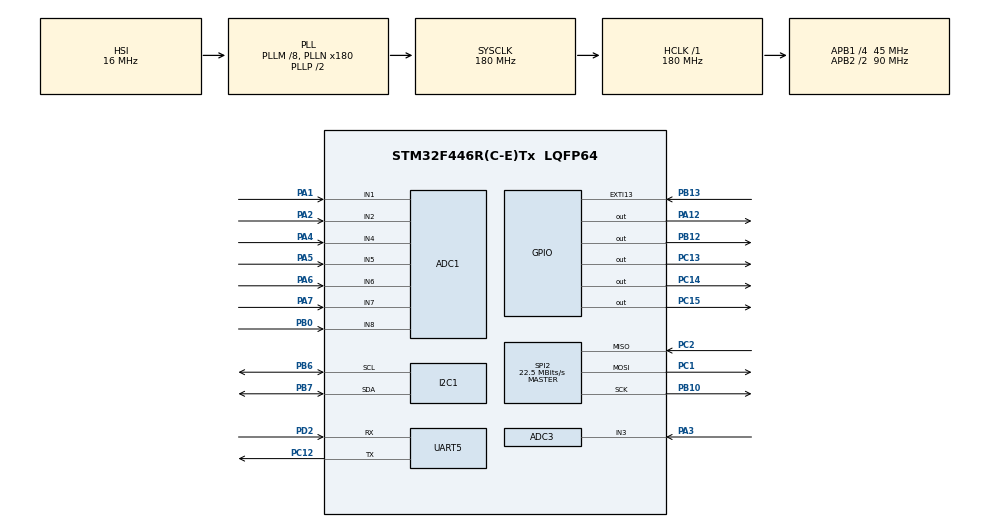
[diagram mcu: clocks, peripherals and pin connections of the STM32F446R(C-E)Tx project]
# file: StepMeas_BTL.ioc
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ADC1.Channel-0\#ChannelRegularConversion=ADC_CHANNEL_7
ADC1.Channel-1\#ChannelRegularConversion=ADC_CHANNEL_8
ADC1.Channel-2\#ChannelRegularConversion=ADC_CHANNEL_1
ADC1.Channel-3\#ChannelRegularConversion=ADC_CHANNEL_2
ADC1.ClockPrescaler=ADC_CLOCK_SYNC_PCLK_DIV6
ADC1.NbrOfConversion=4
ADC1.NbrOfConversionFlag=1
ADC1.Rank-0\#ChannelRegularConversion=1
ADC1.Rank-1\#ChannelRegularConversion=2
ADC1.Rank-2\#ChannelRegularConversion=3
ADC1.Rank-3\#ChannelRegularConversion=4
ADC1.SamplingTime-0\#ChannelRegularConversion=ADC_SAMPLETIME_3CYCLES
ADC1.SamplingTime-1\#ChannelRegularConversion=ADC_SAMPLETIME_3CYCLES
ADC1.SamplingTime-2\#ChannelRegularConversion=ADC_SAMPLETIME_3CYCLES
ADC1.SamplingTime-3\#ChannelRegularConversion=ADC_SAMPLETIME_3CYCLES
ADC1.master=1
ADC3.Channel-0\#ChannelRegularConversion=ADC_CHANNEL_3
ADC3.ClockPrescaler=ADC_CLOCK_SYNC_PCLK_DIV6
ADC3.NbrOfConversionFlag=1
ADC3.Rank-0\#ChannelRegularConversion=1
ADC3.SamplingTime-0\#ChannelRegularConversion=ADC_SAMPLETIME_3CYCLES
Dma.ADC1.0.Direction=DMA_PERIPH_TO_MEMORY
Dma.ADC1.0.FIFOMode=DMA_FIFOMODE_DISABLE
Dma.ADC1.0.Instance=DMA2_Stream0
Dma.ADC1.0.MemDataAlignment=DMA_MDATAALIGN_HALFWORD
Dma.ADC1.0.MemInc=DMA_MINC_ENABLE
Dma.ADC1.0.Mode=DMA_NORMAL
Dma.ADC1.0.PeriphDataAlignment=DMA_PDATAALIGN_HALFWORD
Dma.ADC1.0.PeriphInc=DMA_PINC_DISABLE
Dma.ADC1.0.Priority=DMA_PRIORITY_LOW
Dma.Request0=ADC1
IWDG.Prescaler=IWDG_PRESCALER_32
IWDG.Reload=3500
Mcu.Family=STM32F4
Mcu.Name=STM32F446R(C-E)Tx
Mcu.Package=LQFP64
NVIC.DMA2_Stream0_IRQn=true\:0\:0\:false\:false\:true\:false\:true\:true
NVIC.EXTI15_10_IRQn=true\:0\:0\:false\:false\:true\:true\:true\:true
NVIC.PriorityGroup=NVIC_PRIORITYGROUP_4
NVIC.TIM2_IRQn=true\:0\:0\:false\:false\:true\:true\:true\:true
NVIC.TIM8_TRG_COM_TIM14_IRQn=true\:0\:0\:false\:false\:true\:true\:true\:true
PA1.Signal=ADCx_IN1
PA12.GPIO_PuPd=GPIO_PULLUP
PA12.Signal=GPIO_Output
PA13.Mode=Serial_Wire
PA13.Signal=SYS_JTMS-SWDIO
PA14.Mode=Serial_Wire
PA14.Signal=SYS_JTCK-SWCLK
PA2.Signal=ADCx_IN2
PA3.Signal=ADCx_IN3
PA4.Signal=ADCx_IN4
PA5.Signal=ADCx_IN5
PA6.Signal=ADCx_IN6
PA7.Signal=ADCx_IN7
PB0.Signal=ADCx_IN8
PB10.Mode=Full_Duplex_Master
PB10.Signal=SPI2_SCK
PB12.Signal=GPIO_Output
PB13.Signal=GPXTI13
PB6.Mode=I2C
PB6.Signal=I2C1_SCL
PB7.Mode=I2C
PB7.Signal=I2C1_SDA
PC1.Mode=Full_Duplex_Master
PC1.Signal=SPI2_MOSI
PC12.Mode=Asynchronous
PC12.Signal=UART5_TX
PC13.Signal=GPIO_Output
PC14-OSC32_IN.Signal=GPIO_Output
PC15-OSC32_OUT.Signal=GPIO_Output
PC2.Mode=Full_Duplex_Master
PC2.Signal=SPI2_MISO
PD2.Mode=Asynchronous
PD2.Signal=UART5_RX
PH0-OSC_IN.Mode=HSE-External-Oscillator
PH0-OSC_IN.Signal=RCC_OSC_IN
PH1-OSC_OUT.Mode=HSE-External-Oscillator
PH1-OSC_OUT.Signal=RCC_OSC_OUT
ProjectManager.HeapSize=0x200
ProjectManager.StackSize=0x400
ProjectManager.TargetToolchain=STM32CubeIDE
RCC.48MHZClocksFreq_Value=48000000
RCC.AHBFreq_Value=180000000
RCC.APB1CLKDivider=RCC_HCLK_DIV4
RCC.APB1Freq_Value=45000000
RCC.APB1TimFreq_Value=90000000
RCC.APB2CLKDivider=RCC_HCLK_DIV2
RCC.APB2Freq_Value=90000000
RCC.APB2TimFreq_Value=180000000
RCC.CortexFreq_Value=180000000
RCC.HCLKFreq_Value=180000000
RCC.HSE_VALUE=25000000
RCC.HSI_VALUE=16000000
RCC.PLLM=8
RCC.PLLN=180
RCC.PLLQ=7
RCC.SYSCLKFreq_VALUE=180000000
RCC.SYSCLKSource=RCC_SYSCLKSOURCE_PLLCLK
RCC.USBFreq_Value=51428571.428571425
RCC.VCOOutputFreq_Value=360000000
SH.ADCx_IN1.0=ADC1_IN1,IN1
SH.ADCx_IN2.0=ADC1_IN2,IN2
SH.ADCx_IN3.0=ADC3_IN3,IN3
SH.ADCx_IN3.1=ADC1_IN3,IN3
SH.ADCx_IN4.0=ADC1_IN4,IN4
SH.ADCx_IN5.0=ADC1_IN5,IN5
SH.ADCx_IN6.0=ADC1_IN6,IN6
SH.ADCx_IN7.0=ADC1_IN7,IN7
SH.ADCx_IN8.0=ADC1_IN8,IN8
SPI2.BaudRatePrescaler=SPI_BAUDRATEPRESCALER_2
SPI2.CalculateBaudRate=22.5 MBits/s
SPI2.Direction=SPI_DIRECTION_2LINES
SPI2.Mode=SPI_MODE_MASTER
SPI2.VirtualType=VM_MASTER
TIM14.Period=1000
TIM14.Prescaler=8399
TIM2.Period=55-1
TIM2.Prescaler=45
UART5.VirtualMode=Asynchronous
VP_CRC_VS_CRC.Mode=CRC_Activate
VP_IWDG_VS_IWDG.Mode=IWDG_Activate
VP_TIM14_VS_ClockSourceINT.Mode=Enable_Timer
VP_TIM2_VS_ClockSourceINT.Mode=Internal
board=custom

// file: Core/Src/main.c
/* USER CODE BEGIN Header */
/**
  ******************************************************************************
  * @file           : main.c
  * @brief          : Main program body
  ******************************************************************************
  * @attention
  *
  * <h2><center>&copy; Copyright (c) 2021 STMicroelectronics.
  * All rights reserved.</center></h2>
  *
  * This software component is licensed by ST under Ultimate Liberty license
  * SLA0044, the "License"; You may not use this file except in compliance with
  * the License. You may obtain a copy of the License at:
  *                             www.st.com/SLA0044
  *
  ******************************************************************************
  */
/* USER CODE END Header */
#include "main.h"
#include "adc.h"
#include "crc.h"
#include "dma.h"
#include "i2c.h"
#include "iwdg.h"
#include "spi.h"
#include "tim.h"
#include "usart.h"
#include "gpio.h"

/* USER CODE BEGIN Includes */
#include "bootloader.h"
#include "system_msp.h"
/* USER CODE END Includes */

void SystemClock_Config(void);

int main(void)
{

  /* MCU Configuration--------------------------------------------------------*/

  /* Reset of all peripherals, Initializes the Flash interface and the Systick. */
  HAL_Init();

  /* USER CODE BEGIN Init */
  __enable_irq();
  /* USER CODE END Init */

  /* Configure the system clock */
  SystemClock_Config();

  /* Initialize all configured peripherals */
  MX_GPIO_Init();
  MX_DMA_Init();
  MX_CRC_Init();
  //MX_IWDG_Init();
  MX_TIM14_Init();
  MX_ADC1_Init();
  MX_ADC3_Init();
  MX_SPI2_Init();
  MX_I2C1_Init();
  MX_UART5_Init();
  MX_TIM2_Init();
  /* USER CODE BEGIN 2 */
  Btl_Init();

  /* Led initialization */

  System_Delay(500);
  System_ReloadWdg();

  /* Handle the bootloader */
  Btl_Handle();
  System_ReloadWdg();

  /* Image is not valid*/
  HAL_Delay(2000);
  System_ReloadWdg();

  /* Start the application anyway */
  Btl_StartAppAnyway();
  /* USER CODE END 2 */

  /* Infinite loop */
  while (1)
  {

  }
}

void SystemClock_Config(void)
{
  RCC_OscInitTypeDef RCC_OscInitStruct = {0};
  RCC_ClkInitTypeDef RCC_ClkInitStruct = {0};

  /** Configure the main internal regulator output voltage
  */
  __HAL_RCC_PWR_CLK_ENABLE();
  __HAL_PWR_VOLTAGESCALING_CONFIG(PWR_REGULATOR_VOLTAGE_SCALE1);

  /** Initializes the RCC Oscillators according to the specified parameters
  * in the RCC_OscInitTypeDef structure.
  */
  RCC_OscInitStruct.OscillatorType = RCC_OSCILLATORTYPE_HSI|RCC_OSCILLATORTYPE_LSI;
  RCC_OscInitStruct.HSIState = RCC_HSI_ON;
  RCC_OscInitStruct.HSICalibrationValue = RCC_HSICALIBRATION_DEFAULT;
  RCC_OscInitStruct.LSIState = RCC_LSI_ON;
  RCC_OscInitStruct.PLL.PLLState = RCC_PLL_ON;
  RCC_OscInitStruct.PLL.PLLSource = RCC_PLLSOURCE_HSI;
  RCC_OscInitStruct.PLL.PLLM = 8;
  RCC_OscInitStruct.PLL.PLLN = 180;
  RCC_OscInitStruct.PLL.PLLP = RCC_PLLP_DIV2;
  RCC_OscInitStruct.PLL.PLLQ = 7;
  RCC_OscInitStruct.PLL.PLLR = 2;
  if (HAL_RCC_OscConfig(&RCC_OscInitStruct) != HAL_OK)
  {
    Error_Handler();
  }

  /** Activate the Over-Drive mode
  */
  if (HAL_PWREx_EnableOverDrive() != HAL_OK)
  {
    Error_Handler();
  }

  /** Initializes the CPU, AHB and APB buses clocks
  */
  RCC_ClkInitStruct.ClockType = RCC_CLOCKTYPE_HCLK|RCC_CLOCKTYPE_SYSCLK
                              |RCC_CLOCKTYPE_PCLK1|RCC_CLOCKTYPE_PCLK2;
  RCC_ClkInitStruct.SYSCLKSource = RCC_SYSCLKSOURCE_PLLCLK;
  RCC_ClkInitStruct.AHBCLKDivider = RCC_SYSCLK_DIV1;
  RCC_ClkInitStruct.APB1CLKDivider = RCC_HCLK_DIV4;
  RCC_ClkInitStruct.APB2CLKDivider = RCC_HCLK_DIV2;

  if (HAL_RCC_ClockConfig(&RCC_ClkInitStruct, FLASH_LATENCY_5) != HAL_OK)
  {
    Error_Handler();
  }
}

/* USER CODE BEGIN 4 */
void HAL_TIM_PeriodElapsedCallback(TIM_HandleTypeDef *htim)
{
  if (htim->Instance == TIM14)
  {
    //HAL_GPIO_TogglePin(GPIOD, LED_R_1_Pin|LED_R_2_Pin|LED_G_1_Pin|LED_G_2_Pin);
  }
}
/* USER CODE END 4 */

void Error_Handler(void)
{
  __disable_irq();
  while (1)
  {
  }
}
